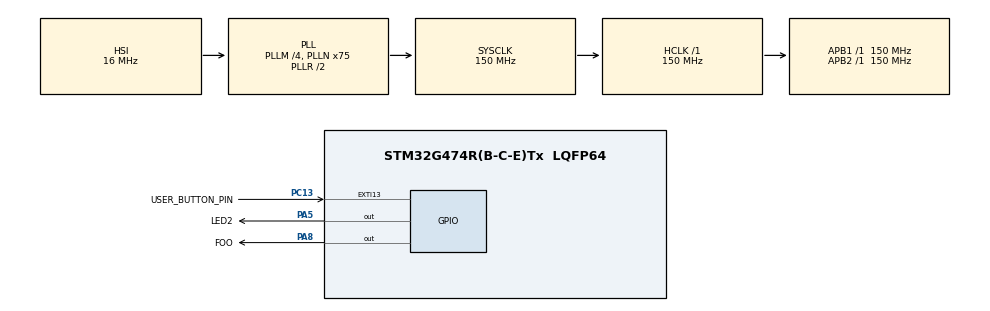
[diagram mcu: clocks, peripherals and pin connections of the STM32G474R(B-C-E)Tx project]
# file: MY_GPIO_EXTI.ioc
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Mcu.Family=STM32G4
Mcu.Name=STM32G474R(B-C-E)Tx
Mcu.Package=LQFP64
NVIC.EXTI15_10_IRQn=true\:2\:0\:true\:false\:true\:true\:true
NVIC.PriorityGroup=NVIC_PRIORITYGROUP_4
PA5.GPIO_Label=LED2
PA5.Signal=GPIO_Output
PA8.GPIO_Label=FOO
PA8.GPIO_Speed=GPIO_SPEED_FREQ_HIGH
PA8.PinState=GPIO_PIN_SET
PA8.Signal=GPIO_Output
PC13.GPIO_Label=USER_BUTTON_PIN
PC13.GPIO_ModeDefaultEXTI=GPIO_MODE_IT_FALLING
PC13.Signal=GPXTI13
ProjectManager.HeapSize=0x200
ProjectManager.StackSize=0x400
ProjectManager.TargetToolchain=SW4STM32
RCC.ADC12Freq_Value=150000000
RCC.ADC345Freq_Value=150000000
RCC.AHBFreq_Value=150000000
RCC.APB1Freq_Value=150000000
RCC.APB1TimFreq_Value=150000000
RCC.APB2Freq_Value=150000000
RCC.APB2TimFreq_Value=150000000
RCC.CortexFreq_Value=150000000
RCC.EXTERNAL_CLOCK_VALUE=12288000
RCC.HCLKFreq_Value=150000000
RCC.HSE_VALUE=24000000
RCC.HSI48_VALUE=16000000
RCC.HSI_VALUE=16000000
RCC.LSE_VALUE=32768
RCC.PLLM=RCC_PLLM_DIV4
RCC.PLLN=75
RCC.SYSCLKFreq_VALUE=150000000
RCC.SYSCLKSource=RCC_SYSCLKSOURCE_PLLCLK
RCC.USBFreq_Value=150000000
RCC.VCOOutputFreq_Value=300000000
VP_SYS_VS_DBSignals.Mode=DisableDeadBatterySignals
board=custom

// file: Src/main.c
/* USER CODE BEGIN Header */
/**
  ******************************************************************************
  * @file           : main.c
  * @brief          : Main program body
  ******************************************************************************
  * @attention
  *
  * <h2><center>&copy; Copyright (c) 2020 STMicroelectronics.
  * All rights reserved.</center></h2>
  *
  * This software component is licensed by ST under BSD 3-Clause license,
  * the "License"; You may not use this file except in compliance with the
  * License. You may obtain a copy of the License at:
  *                        opensource.org/licenses/BSD-3-Clause
  *
  ******************************************************************************
  */
/* USER CODE END Header */

#include "main.h"

void SystemClock_Config(void);
static void MX_GPIO_Init(void);

int main(void)
{

  /* MCU Configuration--------------------------------------------------------*/

  /* Reset of all peripherals, Initializes the Flash interface and the Systick. */
  HAL_Init();

  /* Configure the system clock */
  SystemClock_Config();

  /* Initialize all configured peripherals */
  MX_GPIO_Init();

  /* Infinite loop */
  while (1)
  {

    /* USER CODE BEGIN 3 */
    HAL_GPIO_TogglePin(LED2_GPIO_Port, LED2_Pin);
    HAL_Delay(500);
  }
  /* USER CODE END 3 */
}

void SystemClock_Config(void)
{
  RCC_OscInitTypeDef RCC_OscInitStruct = {0};
  RCC_ClkInitTypeDef RCC_ClkInitStruct = {0};

  /** Configure the main internal regulator output voltage
  */
  HAL_PWREx_ControlVoltageScaling(PWR_REGULATOR_VOLTAGE_SCALE1);
  /** Initializes the CPU, AHB and APB busses clocks
  */
  RCC_OscInitStruct.OscillatorType = RCC_OSCILLATORTYPE_HSI;
  RCC_OscInitStruct.HSIState = RCC_HSI_ON;
  RCC_OscInitStruct.HSICalibrationValue = RCC_HSICALIBRATION_DEFAULT;
  RCC_OscInitStruct.PLL.PLLState = RCC_PLL_ON;
  RCC_OscInitStruct.PLL.PLLSource = RCC_PLLSOURCE_HSI;
  RCC_OscInitStruct.PLL.PLLM = RCC_PLLM_DIV4;
  RCC_OscInitStruct.PLL.PLLN = 75;
  RCC_OscInitStruct.PLL.PLLP = RCC_PLLP_DIV2;
  RCC_OscInitStruct.PLL.PLLQ = RCC_PLLQ_DIV2;
  RCC_OscInitStruct.PLL.PLLR = RCC_PLLR_DIV2;
  if (HAL_RCC_OscConfig(&RCC_OscInitStruct) != HAL_OK)
  {
    Error_Handler();
  }
  /** Initializes the CPU, AHB and APB busses clocks
  */
  RCC_ClkInitStruct.ClockType = RCC_CLOCKTYPE_HCLK|RCC_CLOCKTYPE_SYSCLK
                              |RCC_CLOCKTYPE_PCLK1|RCC_CLOCKTYPE_PCLK2;
  RCC_ClkInitStruct.SYSCLKSource = RCC_SYSCLKSOURCE_PLLCLK;
  RCC_ClkInitStruct.AHBCLKDivider = RCC_SYSCLK_DIV1;
  RCC_ClkInitStruct.APB1CLKDivider = RCC_HCLK_DIV1;
  RCC_ClkInitStruct.APB2CLKDivider = RCC_HCLK_DIV1;

  if (HAL_RCC_ClockConfig(&RCC_ClkInitStruct, FLASH_LATENCY_7) != HAL_OK)
  {
    Error_Handler();
  }
}

static void MX_GPIO_Init(void)
{
  GPIO_InitTypeDef GPIO_InitStruct = {0};

  /* GPIO Ports Clock Enable */
  __HAL_RCC_GPIOC_CLK_ENABLE();
  __HAL_RCC_GPIOA_CLK_ENABLE();

  /*Configure GPIO pin Output Level */
  HAL_GPIO_WritePin(LED2_GPIO_Port, LED2_Pin, GPIO_PIN_RESET);

  /*Configure GPIO pin Output Level */
  HAL_GPIO_WritePin(FOO_GPIO_Port, FOO_Pin, GPIO_PIN_SET);

  /*Configure GPIO pin : USER_BUTTON_PIN_Pin */
  GPIO_InitStruct.Pin = USER_BUTTON_PIN_Pin;
  GPIO_InitStruct.Mode = GPIO_MODE_IT_FALLING;
  GPIO_InitStruct.Pull = GPIO_NOPULL;
  HAL_GPIO_Init(USER_BUTTON_PIN_GPIO_Port, &GPIO_InitStruct);

  /*Configure GPIO pin : LED2_Pin */
  GPIO_InitStruct.Pin = LED2_Pin;
  GPIO_InitStruct.Mode = GPIO_MODE_OUTPUT_PP;
  GPIO_InitStruct.Pull = GPIO_NOPULL;
  GPIO_InitStruct.Speed = GPIO_SPEED_FREQ_LOW;
  HAL_GPIO_Init(LED2_GPIO_Port, &GPIO_InitStruct);

  /*Configure GPIO pin : FOO_Pin */
  GPIO_InitStruct.Pin = FOO_Pin;
  GPIO_InitStruct.Mode = GPIO_MODE_OUTPUT_PP;
  GPIO_InitStruct.Pull = GPIO_NOPULL;
  GPIO_InitStruct.Speed = GPIO_SPEED_FREQ_HIGH;
  HAL_GPIO_Init(FOO_GPIO_Port, &GPIO_InitStruct);

  /* EXTI interrupt init*/
  HAL_NVIC_SetPriority(EXTI15_10_IRQn, 2, 0);
  HAL_NVIC_EnableIRQ(EXTI15_10_IRQn);

}

/* USER CODE BEGIN 4 */
/**
  * @brief EXTI line detection callbacks
  * @param GPIO_Pin: Specifies the pins connected EXTI line
  * @retval None
  */
void HAL_GPIO_EXTI_Callback(uint16_t GPIO_Pin)
{
  if (GPIO_Pin == USER_BUTTON_PIN_Pin)
  {
    HAL_GPIO_TogglePin(FOO_GPIO_Port, FOO_Pin);
  }
}
/* USER CODE END 4 */

void Error_Handler(void)
{
}

/************************ (C) COPYRIGHT STMicroelectronics *****END OF FILE****/
